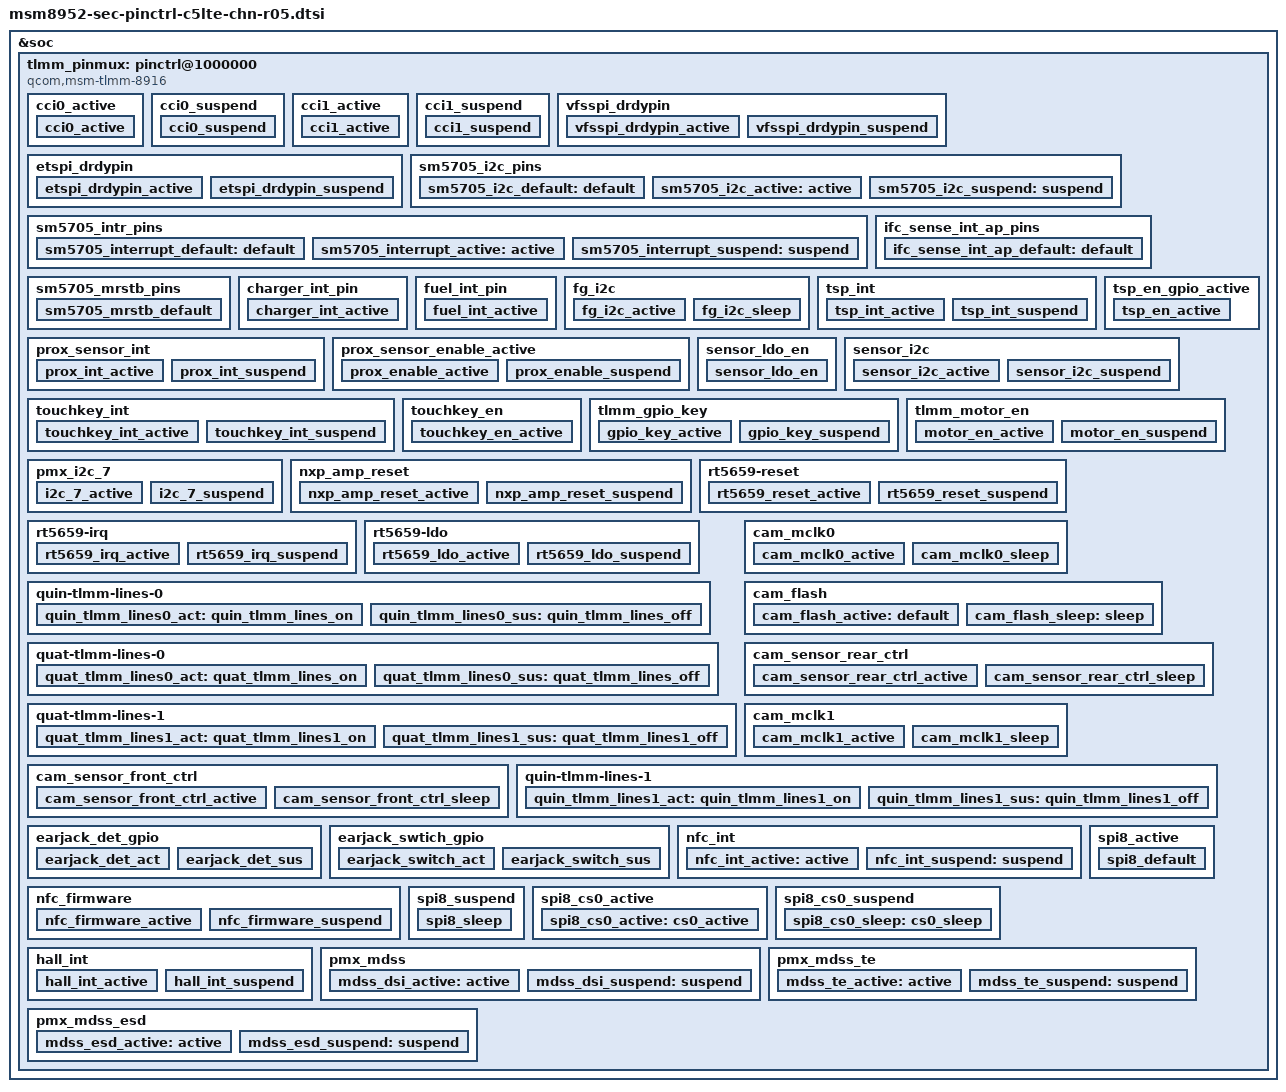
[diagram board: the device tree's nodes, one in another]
/*
 * Copyright (c) 2014-2015, The Linux Foundation. All rights reserved.
 *
 * This program is free software; you can redistribute it and/or modify
 * it under the terms of the GNU General Public License version 2 and
 * only version 2 as published by the Free Software Foundation.
 *
 * This program is distributed in the hope that it will be useful,
 * but WITHOUT ANY WARRANTY; without even the implied warranty of
 * MERCHANTABILITY or FITNESS FOR A PARTICULAR PURPOSE.  See the
 * GNU General Public License for more details.
 */

/* Pinctrl device tree file for c5lte chn open REV0.5 */

&tlmm_pinmux {
	/* MUIC - SM5705 */
	sm5705_i2c_pins {
		qcom,pins = <&gp 14>, <&gp 15>; /* SDA, SCL */
		qcom,num-grp-pins = <2>;
		qcom,pin-func = <0>;
		label = "sm5705_gpio";
		sm5705_i2c_default: default {
			drive-strength = <2>;
			bias-disable;
		};
		sm5705_i2c_active: active {
			drive-strength = <2>;
			bias-disable;
		};
		sm5705_i2c_suspend: suspend {
			drive-strength = <2>;
			bias-disable;
		};
	};

	sm5705_intr_pins {
		qcom,pins = <&gp 35>;
		qcom,num-grp-pins = <1>;
		qcom,pin-func = <0>;
		label = "sm5705_gpio_int";
		sm5705_interrupt_default: default {
			drive-strength = <2>;
			bias-disable;
		};
		sm5705_interrupt_active: active {
			drive-strength = <2>;
			bias-disable;
		};
		sm5705_interrupt_suspend: suspend {
			drive-strength = <2>;
			bias-disable;
		};
	};
	ifc_sense_int_ap_pins {
		qcom,pins = <&gp 90>;
		qcom,num-grp-pins = <1>;
		qcom,pin-func = <0>;
		label = "ifc_sense_int_ap";
		ifc_sense_int_ap_default: default {
			drive-strength = <2>;
			bias-disable;
		};
	};

	sm5705_mrstb_pins {
		qcom,pins = <&gp 47>;
		qcom,num-grp-pins = <1>;
		qcom,pin-func = <0>;
		label = "sm5705_mrstb_pins";
		sm5705_mrstb_default: sm5705_mrstb_default {
			drive-strength = <2>;
			bias-disable;
		};
	};

	charger_int_pin {
		qcom,pins = <&gp 44>;
		qcom,num-grp-pins = <1>;
		qcom,pin-func = <0>;
		label = "charger_int_gpio";
		charger_int_active: charger_int_active {
			drive-strength = <2>;
			bias-disable;         /* No PULL */
		};
	};

	fuel_int_pin {
		qcom,pins = <&gp 62>;
		qcom,num-grp-pins = <1>;
		qcom,pin-func = <0>;
		label = "fuel_int_gpio";
		fuel_int_active: fuel_int_active {
			drive-strength = <2>;
			bias-disable;         /* No PULL */
			input-enable;
		};
	};

	fg_i2c {
		/* CLK, DATA */
		qcom,pins = <&gp 22>, <&gp 23>;
		qcom,num-grp-pins = <2>;
		qcom,pin-func = <0>;
		label = "fg_i2c";

		fg_i2c_active: fg_i2c_active {
			drive-strength = <2>;	/* 2 MA */
			bias-disable; /* No PULL */
		};

		fg_i2c_sleep: fg_i2c_sleep {
			drive-strength = <2>;	/* 2 MA */
			bias-disable; /* No PULL */
		};
	};

	tsp_int {
		qcom,pins = <&gp 65>; /* INTERRUPT */
		qcom,num-grp-pins = <1>;
		qcom,pin-func = <0>;
		label = "tsp_int";
		tsp_int_active: tsp_int_active {
			drive-strength = <2>;
			bias-disable;
		};
		tsp_int_suspend: tsp_int_suspend {
			drive-strength = <2>;
			bias-disable;
		};
	};

	tsp_en_gpio_active {
		qcom,pins = <&gp 60>;
		qcom,num-grp-pins = <1>;
		qcom,pin-func = <0>;
		label = "tsp_en_gpio";
		tsp_en_active: tsp_en_active {
			drive-strength = <2>;
			bias-pull-down; /* PULL DOWN*/
		};
	};

	/* add pingrp for proximity sensors  */
	prox_sensor_int {
		qcom,pins = <&gp 43>;
		qcom,pin-func = <3>;
		qcom,num-grp-pins = <1>;
		label = "prox_sensor_int";
		prox_int_active: prox_int_active {
			drive-strength = <2>;
			bias-disable; /* No PULL */
		};
		prox_int_suspend: prox_int_suspend {
			drive-strength = <2>;
			bias-disable; /* No PULL */
		};
	};

	prox_sensor_enable_active {
		qcom,pins = <&gp 64>;
		qcom,pin-func = <0>;
		qcom,num-grp-pins = <1>;
		label = "prox_sensor_enable_active";
		prox_enable_active: prox_enable_active {
			drive-strength = <2>;
			bias-disable; /* No PULL */
		};
		prox_enable_suspend: prox_enable_suspend {
			drive-strength = <2>;
			bias-disable; /* No PULL */
	};
	};


	sensor_ldo_en {
		qcom,pins = <&gp 68>;
		qcom,pin-func = <0>;
		qcom,num-grp-pins = <1>;
		label = "sensor_ldo_en";
		sensor_ldo_en: sensor_ldo_en {
			drive-strength = <2>;
			output-high;
			bias-disable = <0>; /* No PULL */
		};
	};

	sensor_i2c {
		qcom,pins = <&gp 18>, <&gp 19>; /* SDA, SCL */
		qcom,num-grp-pins = <2>;
		qcom,pin-func = <0>;
		label = "sensor_i2c";
		sensor_i2c_active: sensor_i2c_active {
			drive-strength = <2>;
			bias-disable;
		};
		sensor_i2c_suspend: sensor_i2c_suspend {
			drive-strength = <2>;
			bias-disable;
		};
	};

	touchkey_int {
		qcom,pins = <&gp 46>; /* INTERRUPT */
		qcom,num-grp-pins = <1>;
		qcom,pin-func = <0>;
		label = "touchkey_int";
		touchkey_int_active: touchkey_int_active {
			drive-strength = <2>;
			bias-disable;
		};
		touchkey_int_suspend: touchkey_int_suspend {
			drive-strength = <2>;
			bias-disable;
		};
	};

	touchkey_en {
		qcom,pins = <&gp 128>;
		qcom,num-grp-pins = <1>;
		qcom,pin-func = <0>;
		label = "touchkey_en";
		touchkey_en_active: touchkey_en_active {
			drive-strength = <2>;
			bias-pull-down; /* PULL DOWN*/
		};
	};

	tlmm_gpio_key {
		qcom,pins = <&gp 45>, <&gp 85>;
		qcom,pin-func = <0>;
		qcom,num-grp-pins = <2>;
		label = "tlmm_gpio_key";
		gpio_key_active: gpio_key_active {
			drive-strength = <2>;
			bias-pull-up;
		};
		gpio_key_suspend: gpio_key_suspend {
			drive-strength = <2>;
			bias-pull-up;
		};
	};

	tlmm_motor_en {
		qcom,pins = <&gp 64>;
		qcom,pin-func = <0>;
		qcom,num-grp-pins = <1>;
		label = "tlmm_motor_en";
		motor_en_active: motor_en_active {
			drive-strength = <2>;
			bias-pull-down;
		};
		motor_en_suspend: motor_en_suspend {
			drive-strength = <2>;
			bias-pull-down;
		};
	};
	
	pmx_i2c_7 {
		/* CLK, DATA */
		qcom,pins = <&gp 94>, <&gp 95>;
		qcom,num-grp-pins = <2>;
		qcom,pin-func = <4>;
		label = "pmx_i2c_7";
		/* active state */
		i2c_7_active: i2c_7_active{
			drive-strength = <2>;
			bias-pull-up;
		};
		/* suspend state */
		i2c_7_suspend: i2c_7_suspend {
			drive-strength = <2>;
			bias-pull-up;
		};
	};

	nxp_amp_reset {
		qcom,pins = <&gp 129>;
		qcom,num-grp-pins = <1>;
		qcom,pin-func = <0>;
		label = "nxp_amp_reset";
		nxp_amp_reset_active: nxp_amp_reset_active {
			drive-strength = <2>;
			bias-disable;
		};
		nxp_amp_reset_suspend: nxp_amp_reset_suspend {
			drive-strength = <2>;
			bias-disable;
		};
	};
	
	rt5659-reset {
		qcom,pins = <&gp 40>;
		qcom,num-grp-pins = <1>;
		qcom,pin-func = <0>;
		label = "rt5659-reset";
		rt5659_reset_active: rt5659_reset_active {
			drive-strength = <2>;
			bias-disable;
		};
		rt5659_reset_suspend: rt5659_reset_suspend {
			drive-strength = <2>;
			bias-disable;
		};
	};
	
	rt5659-irq {
		qcom,pins = <&gp 36>;
		qcom,num-grp-pins = <1>;
		qcom,pin-func = <0>;
		label = "rt5659-irq";
		rt5659_irq_active: rt5659_irq_active {
			drive-strength = <2>;
			bias-disable;
		};
		rt5659_irq_suspend: rt5659_irq_suspend {
			drive-strength = <2>;
			bias-disable;
		};
	};

	rt5659-ldo {
		qcom,pins = <&gp 39>;
		qcom,num-grp-pins = <1>;
		qcom,pin-func = <0>;
		label = "rt5659-ldo";
		rt5659_ldo_active: rt5659_ldo_active {
			drive-strength = <2>;
			bias-disable;
		};
		rt5659_ldo_suspend: rt5659_ldo_suspend {
			drive-strength = <2>;
			bias-disable;
		};
	};	
	
	quin-tlmm-lines-0 {
		qcom,pins = <&gp 88>, <&gp 91>;
		qcom,num-grp-pins = <2>;
		qcom,pin-func = <1>;
		label = "quin-lines-0";
		quin_tlmm_lines0_act: quin_tlmm_lines_on {
			drive-strength = <8>;
			bias-pull-none;
		};
		quin_tlmm_lines0_sus: quin_tlmm_lines_off {
			drive-strength = <2>;
			bias-pull-none;
		};
	};
	
	quat-tlmm-lines-0 {
		qcom,pins = <&gp 13>, <&gp 8>;
		qcom,num-grp-pins = <2>;
		qcom,pin-func = <3>;
		label = "quat-lines-0";
		quat_tlmm_lines0_act: quat_tlmm_lines_on {
			drive-strength = <8>;
			bias-disable;
		};
		quat_tlmm_lines0_sus: quat_tlmm_lines_off {
			drive-strength = <2>;
			bias-disable;
		};
	};
 
	quat-tlmm-lines-1 {
		qcom,pins = <&gp 9>, <&gp 12>;
		qcom,num-grp-pins = <2>;
		qcom,pin-func = <3>;
		label = "quat-lines-1";
		quat_tlmm_lines1_act: quat_tlmm_lines1_on {
			drive-strength = <8>;
			bias-disable;
		};
		quat_tlmm_lines1_sus: quat_tlmm_lines1_off {
			drive-strength = <2>;
			bias-disable;
		};
	};


	cam_mclk0 {
		qcom,pins = <&gp 26>;
		qcom,num-grp-pins = <1>;
		qcom,pin-func = <1>;
		label = "cam_mclk0";
		cam_mclk0_active: cam_mclk0_active {
			drive-strength = <4>;
			output-low;
			bias-pull-down=<0>;
		};
		cam_mclk0_sleep: cam_mclk0_sleep {
			drive-strength = <4>;
			output-low;
			bias-pull-down=<0>;
		};
	};


	cam_flash {
		qcom,pins = <&gp 33>, <&gp 34>;
		qcom,num-grp-pins = <2>;
		qcom,pin-func = <0>;
		label = "cam_flash";

		cam_flash_active: default {
			drive-strength = <2>;	/* 2 MA */
			bias-pull-down = <0>; /* PULL DOWN */
			output-low;
		};
		cam_flash_sleep: sleep {
			drive-strength = <2>;	/* 2 MA */
			bias-pull-down = <0>; /* PULL DOWN */
			output-low;
		};
	};

      cam_sensor_rear_ctrl {
		qcom,pins = <&gp 69>,<&gp 86>;
		qcom,num-grp-pins = <2>;
		label = "cam_sensor_rear_ctrl";
		cam_sensor_rear_ctrl_active: cam_sensor_rear_ctrl_active {
			drive-strength = <2>;
			bias-disable = <0>;
		};
		cam_sensor_rear_ctrl_sleep: cam_sensor_rear_ctrl_sleep {
			drive-strength = <2>;
			bias-pull-down = <0>;
		};
	};
	
	cam_mclk1 {
		qcom,pins = <&gp 28>;
		qcom,num-grp-pins = <1>;
		qcom,pin-func = <1>;
		label = "cam_mclk1";
		cam_mclk1_active: cam_mclk1_active {
			drive-strength = <4>;
			output-low;
			bias-pull-down = <0>;
		};
		cam_mclk1_sleep: cam_mclk1_sleep {
			drive-strength = <4>;
			output-low;
			bias-pull-down = <0>;
		};
	};

	cam_sensor_front_ctrl {
		qcom,pins = <&gp 49>,<&gp 74>;
		qcom,num-grp-pins = <2>;
		label = "cam_sensor_front_ctrl";
		cam_sensor_front_ctrl_active: cam_sensor_front_ctrl_active {
			drive-strength = <2>;
			bias-disable = <0>;
		};
		cam_sensor_front_ctrl_sleep: cam_sensor_front_ctrl_sleep {
			drive-strength = <2>;
			bias-disable = <0>; 
		};
	};
	
	quin-tlmm-lines-1 {
		qcom,pins = <&gp 92>, <&gp 93>;
		qcom,num-grp-pins = <2>;
		qcom,pin-func = <3>;
		label = "quin-lines-1";
		quin_tlmm_lines1_act: quin_tlmm_lines1_on {
			drive-strength = <8>;
			bias-pull-none;
		};
		quin_tlmm_lines1_sus: quin_tlmm_lines1_off {
			drive-strength = <2>;
			bias-pull-none;
		};
	};
	/delete-node/ tpiu_seta_18;
	/delete-node/ pri-tlmm-lines;

	earjack_det_gpio {
		  qcom,pins = <&gp 86>;
		  qcom,pin-func = <0>;
		  qcom,num-grp-pins = <1>;
		  label = "earjack_det_gpio";
		  earjack_det_act: earjack_det_act {
				drive-strength = <2>;
				bias-disable;
		  };
		  earjack_det_sus: earjack_det_sus {
				drive-strength = <2>;
				bias-disable;
		  };
	};

	earjack_swtich_gpio {
		  qcom,pins = <&gp 38>;
		  qcom,pin-func = <0>;
		  qcom,num-grp-pins = <1>;
		  label = "earjack_swtich_gpio";
		  earjack_switch_act: earjack_switch_act {
				drive-strength = <2>;
				bias-disable;
		  };
		  earjack_switch_sus: earjack_switch_sus {
				drive-strength = <2>;
				bias-disable;
		  };
	};

	/delete-node/ pmx_rd_nfc_int;
	nfc_int {
		qcom,pins = <&gp 17>;
		qcom,pin-func = <0>;
		qcom,num-grp-pins = <1>;
		label = "pmx_nfc_int";

		nfc_int_active: active {
			drive-strength = <6>;
			bias-pull-down;
		};

		nfc_int_suspend: suspend {
			drive-strength = <6>;
			bias-pull-down;
		};
	};

	nfc_firmware {
		qcom,pins = <&gp 16>;
		qcom,pin-func = <0>;
		qcom,num-grp-pins = <1>;
		label = "nfc_firmware";

		nfc_firmware_active: nfc_firmware_active {
			drive-strength = <2>;
			bias-pull-down; /* PULL DOWN */
		};

		nfc_firmware_suspend: nfc_firmware_suspend {
			drive-strength = <2>;
			bias-pull-down; /* PULL DOWN */
		};
	};

	spi8_active {
		/* MOSI, MISO*/
		qcom,pins = <&gp 96>, <&gp 97>;
		qcom,num-grp-pins = <2>;
		qcom,pin-func = <1>;
		label = "spi8-active";
		/* active state */
		spi8_default: spi8_default {
			drive-strength = <12>; /* 12 MA */
			bias-disable = <0>; /* No PULL */
		};
	};

	spi8_suspend {
		/* MOSI, MISO*/
		qcom,pins = <&gp 96>, <&gp 97>;
		qcom,num-grp-pins = <2>;
		qcom,pin-func = <1>;
		label = "spi8-suspend";
		/* suspended state */
		spi8_sleep: spi8_sleep {
			drive-strength = <2>; /* 2 MA */
			bias-disable = <0>; /* No PULL */
		};
	};

	spi8_cs0_active {
		/* CS, CLK */
		qcom,pins = <&gp 98>, <&gp 99>;
		qcom,num-grp-pins = <2>;
		qcom,pin-func = <2>;
		label = "spi8-cs0-active";

		spi8_cs0_active: cs0_active {
			drive-strength = <2>;
			bias-disable = <0>;
		};
	};

	spi8_cs0_suspend {
		/* CS, CLK */
		qcom,pins = <&gp 98>, <&gp 99>;
		qcom,num-grp-pins = <2>;
		qcom,pin-func = <2>;
		label = "spi8-cs0-suspend";

		spi8_cs0_sleep: cs0_sleep {
			drive-strength = <2>;
			bias-disable = <0>;
		};
	};

	hall_int {
                qcom,pins = <&gp 48>; /* INTERRUPT */
                qcom,num-grp-pins = <1>;
                qcom,pin-func = <0>;
                label = "hall_int";
                hall_int_active: hall_int_active {
			drive-strength = <2>;
                        bias-disable;
                };
                hall_int_suspend: hall_int_suspend {
			drive-strength = <2>;
                        bias-disable;
                };
        };

	pmx_mdss: pmx_mdss {			// GPIO 41 & 61
		label = "mdss-pins";
		qcom,pin-func = <0>;
		mdss_dsi_active: active {
			drive-strength = <8>;
			bias-disable = <0>;	// no pull
		};
		mdss_dsi_suspend: suspend {
			drive-strength = <2>;
			bias-pull-down;
		};
	};

	pmx_mdss_te: pmx_mdss_te {		// GPIO 24
		label = "mdss-te-pin";
		qcom,pin-func = <1>;
		mdss_te_active: active {
			drive-strength = <2>;
			bias-pull-down;
			input-debounce = <0>;
		};
		mdss_te_suspend: suspend {
			drive-strength = <2>;
			bias-pull-down;
			input-debounce = <0>;
		};
	};

	pmx_mdss_esd: pmx_mdss_esd {		// GPIO 13 & 54
		label = "mdss-esd-pin";
		qcom,pin-func = <0>;
		mdss_esd_active: active {
			drive-strength = <2>;
			bias-disable = <0>;	// no pull
		};
		mdss_esd_suspend: suspend {
			drive-strength = <2>;
			bias-disable = <0>;	// no pull
		};
	};
};

&soc {
	tlmm_pinmux: pinctrl@1000000 {
		compatible = "qcom,msm-tlmm-8916";
		reg = <0x1000000 0x300000>;
		interrupts = <0 208 0>;

		/* cci */
		cci0_active {
			/* CLK, DATA */
			qcom,pins = <&gp 29>, <&gp 30>;
			qcom,num-grp-pins = <2>;
			qcom,pin-func = <1>;
			label = "cci0-active";
			/* active state */
			cci0_active: cci0_active {
				drive-strength = <2>; /* 2 MA */
				bias-disable = <0>; /* No PULL */
			};
		};

		cci0_suspend {
			/* CLK, DATA */
			qcom,pins = <&gp 29>, <&gp 30>;
			qcom,num-grp-pins = <2>;
			qcom,pin-func = <0>;
			label = "cci0-suspend";
			/*suspended state */
			cci0_suspend: cci0_suspend {
				drive-strength = <2>; /* 2 MA */
				bias-disable = <0>; /* No PULL */
			};
		};

		cci1_active {
			/* CLK, DATA */
			qcom,pins = <&gp 31>, <&gp 32>;
			qcom,num-grp-pins = <2>;
			qcom,pin-func = <1>;
			label = "cci1-active";
			/* active state */
			cci1_active: cci1_active {
				drive-strength = <2>; /* 2 MA */
				bias-disable=<0>; /* No PULL */
			};
		};

		cci1_suspend {
			/* CLK, DATA */
			qcom,pins = <&gp 31>, <&gp 32>;
			qcom,num-grp-pins = <2>;
			qcom,pin-func = <0>;
			label = "cci1-suspend";
			/*suspended state */
			cci1_suspend: cci1_suspend {
				drive-strength = <2>; /* 2 MA */
				bias-disable=<0>; /* No PULL */
			};
		};

		vfsspi_drdypin: vfsspi_drdypin {
			qcom,pins = <&gp 37>;
			qcom,pin-func = <0>;
			qcom,num-grp-pins = <1>;
			label = "vfsspi_drdypin";
			vfsspi_drdypin_active: vfsspi_drdypin_active {
				drive-strength = <2>;
				bias-pull-down;
			};
			vfsspi_drdypin_suspend: vfsspi_drdypin_suspend {
				drive-strength = <2>;
				bias-pull-down;
			};
		};

		etspi_drdypin: etspi_drdypin {
			qcom,pins = <&gp 37>;
			qcom,pin-func = <0>;
			qcom,num-grp-pins = <1>;
			label = "etspi_drdypin";
			etspi_drdypin_active: etspi_drdypin_active {
				drive-strength = <2>;
				bias-pull-down;
			};
			etspi_drdypin_suspend: etspi_drdypin_suspend {
				drive-strength = <2>;
				bias-pull-down;
			};
		};
	};
};
